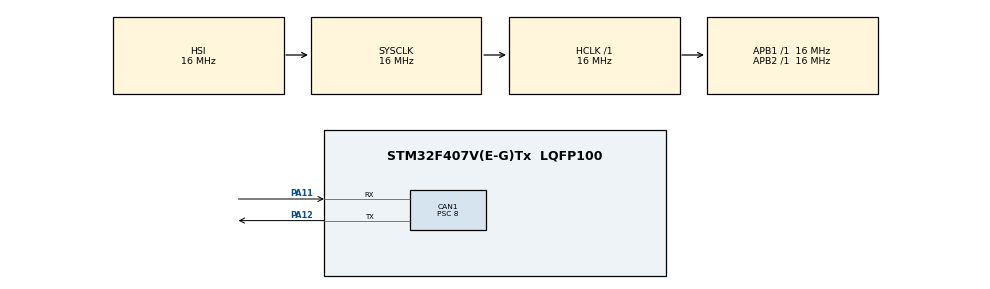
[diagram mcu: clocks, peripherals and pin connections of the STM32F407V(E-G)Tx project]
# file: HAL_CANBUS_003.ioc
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CAN1.BS1=CAN_BS1_2TQ
CAN1.CalculateBaudRate=500000
CAN1.CalculateTimeBit=2000
CAN1.CalculateTimeQuantum=500.0
CAN1.Mode=CAN_MODE_LOOPBACK
CAN1.Prescaler=8
Mcu.Family=STM32F4
Mcu.Name=STM32F407V(E-G)Tx
Mcu.Package=LQFP100
NVIC.CAN1_RX0_IRQn=true\:0\:0\:false\:false\:true\:true\:true\:true
NVIC.CAN1_RX1_IRQn=true\:0\:0\:false\:false\:true\:true\:true\:true
NVIC.PriorityGroup=NVIC_PRIORITYGROUP_4
PA11.Mode=CAN_Activate
PA11.Signal=CAN1_RX
PA12.Mode=CAN_Activate
PA12.Signal=CAN1_TX
PA13.Mode=Serial_Wire
PA13.Signal=SYS_JTMS-SWDIO
PA14.Mode=Serial_Wire
PA14.Signal=SYS_JTCK-SWCLK
PH0-OSC_IN.Mode=HSE-External-Clock-Source
PH0-OSC_IN.Signal=RCC_OSC_IN
PH1-OSC_OUT.Mode=HSE-External-Clock-Source
PH1-OSC_OUT.Signal=RCC_OSC_OUT
ProjectManager.HeapSize=0x200
ProjectManager.StackSize=0x400
ProjectManager.TargetToolchain=STM32CubeIDE
RCC.AHBFreq_Value=16000000
RCC.APB1Freq_Value=16000000
RCC.APB2Freq_Value=16000000
RCC.CortexFreq_Value=16000000
RCC.HSE_VALUE=25000000
RCC.HSI_VALUE=16000000
RCC.LSE_VALUE=32768
RCC.SYSCLKFreq_VALUE=16000000
RCC.VCOOutputFreq_Value=192000000
board=custom

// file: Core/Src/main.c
/* USER CODE BEGIN Header */
/**
  ******************************************************************************
  * @file           : main.c
  * @brief          : Main program body
  ******************************************************************************
  * @attention
  *
  * Copyright (c) 2024 STMicroelectronics.
  * All rights reserved.
  *
  * This software is licensed under terms that can be found in the LICENSE file
  * in the root directory of this software component.
  * If no LICENSE file comes with this software, it is provided AS-IS.
  *
  ******************************************************************************
  */
/* USER CODE END Header */
#include "main.h"

/* USER CODE BEGIN Includes */

CAN_TxHeaderTypeDef CanTxHeader;
CAN_RxHeaderTypeDef CanRxHeader;

uint32_t TxMailbox;
uint8_t TxData[8];
uint8_t RxData[8];
uint8_t count = 0;

/* USER CODE END Includes */

CAN_HandleTypeDef hcan1;

void SystemClock_Config(void);
static void MX_GPIO_Init(void);
static void MX_CAN1_Init(void);

/* USER CODE BEGIN 0 */

void HAL_CAN_RxFifo0MsgPendingCallback(CAN_HandleTypeDef *hcan)
{
	HAL_CAN_GetRxMessage(&hcan1, CAN_RX_FIFO0 ,&CanRxHeader , RxData);

}

/* USER CODE END 0 */

int main(void)
{

  /* MCU Configuration--------------------------------------------------------*/

  /* Reset of all peripherals, Initializes the Flash interface and the Systick. */
  HAL_Init();

  /* Configure the system clock */
  SystemClock_Config();

  /* Initialize all configured peripherals */
  MX_GPIO_Init();
  MX_CAN1_Init();
  /* USER CODE BEGIN 2 */

  HAL_CAN_Start(&hcan1);
  HAL_CAN_ActivateNotification(&hcan1, CAN_IT_RX_FIFO0_MSG_PENDING);

  CanTxHeader.DLC = 1;
  CanTxHeader.ExtId = 0;
  CanTxHeader.IDE = CAN_ID_STD;
  CanTxHeader.RTR = CAN_RTR_DATA;
  CanTxHeader.StdId = 0x103;
  CanTxHeader.TransmitGlobalTime = DISABLE;

  TxData[0] = 0xf3;

  HAL_CAN_AddTxMessage(&hcan1, &CanTxHeader, TxData, &TxMailbox);

  /* USER CODE END 2 */

  /* Infinite loop */
  while (1)
  {

  }
}

void SystemClock_Config(void)
{
  RCC_OscInitTypeDef RCC_OscInitStruct = {0};
  RCC_ClkInitTypeDef RCC_ClkInitStruct = {0};

  /** Configure the main internal regulator output voltage
  */
  __HAL_RCC_PWR_CLK_ENABLE();
  __HAL_PWR_VOLTAGESCALING_CONFIG(PWR_REGULATOR_VOLTAGE_SCALE1);

  /** Initializes the RCC Oscillators according to the specified parameters
  * in the RCC_OscInitTypeDef structure.
  */
  RCC_OscInitStruct.OscillatorType = RCC_OSCILLATORTYPE_HSI;
  RCC_OscInitStruct.HSIState = RCC_HSI_ON;
  RCC_OscInitStruct.HSICalibrationValue = RCC_HSICALIBRATION_DEFAULT;
  RCC_OscInitStruct.PLL.PLLState = RCC_PLL_NONE;
  if (HAL_RCC_OscConfig(&RCC_OscInitStruct) != HAL_OK)
  {
    Error_Handler();
  }

  /** Initializes the CPU, AHB and APB buses clocks
  */
  RCC_ClkInitStruct.ClockType = RCC_CLOCKTYPE_HCLK|RCC_CLOCKTYPE_SYSCLK
                              |RCC_CLOCKTYPE_PCLK1|RCC_CLOCKTYPE_PCLK2;
  RCC_ClkInitStruct.SYSCLKSource = RCC_SYSCLKSOURCE_HSI;
  RCC_ClkInitStruct.AHBCLKDivider = RCC_SYSCLK_DIV1;
  RCC_ClkInitStruct.APB1CLKDivider = RCC_HCLK_DIV1;
  RCC_ClkInitStruct.APB2CLKDivider = RCC_HCLK_DIV1;

  if (HAL_RCC_ClockConfig(&RCC_ClkInitStruct, FLASH_LATENCY_0) != HAL_OK)
  {
    Error_Handler();
  }
}

static void MX_CAN1_Init(void)
{

  hcan1.Instance = CAN1;
  hcan1.Init.Prescaler = 8;
  hcan1.Init.Mode = CAN_MODE_LOOPBACK;
  hcan1.Init.SyncJumpWidth = CAN_SJW_1TQ;
  hcan1.Init.TimeSeg1 = CAN_BS1_2TQ;
  hcan1.Init.TimeSeg2 = CAN_BS2_1TQ;
  hcan1.Init.TimeTriggeredMode = DISABLE;
  hcan1.Init.AutoBusOff = DISABLE;
  hcan1.Init.AutoWakeUp = DISABLE;
  hcan1.Init.AutoRetransmission = DISABLE;
  hcan1.Init.ReceiveFifoLocked = DISABLE;
  hcan1.Init.TransmitFifoPriority = DISABLE;
  if (HAL_CAN_Init(&hcan1) != HAL_OK)
  {
    Error_Handler();
  }

  // First set the Can Filter Header.
  CAN_FilterTypeDef CanFilter;

  // Enable or the disable the filter.
  CanFilter.FilterActivation = CAN_FILTER_ENABLE;

  // This parameter specifies which filter bank we want to use. It could be anything between 0 and SlaveStartFilterBank-1
  CanFilter.FilterBank = 10;

  // Select which Filter FIFO to use. In our case it is the FIFO0;
  CanFilter.FilterFIFOAssignment = CAN_FILTER_FIFO0;
  CanFilter.FilterIdHigh 	 = 0x103 << 5;
  CanFilter.FilterIdLow 	 = 0;
  CanFilter.FilterMaskIdHigh = 0x103 << 5;
  CanFilter.FilterMaskIdLow  = 0;
  CanFilter.FilterMode = CAN_FILTERMODE_IDMASK;
  CanFilter.FilterScale = CAN_FILTERSCALE_32BIT;

  // This parameter shows how much filters we want to assign to CAN1 peripheral.
  CanFilter.SlaveStartFilterBank = 13;

  HAL_CAN_ConfigFilter(&hcan1, &CanFilter);
}

static void MX_GPIO_Init(void)
{

  /* GPIO Ports Clock Enable */
  __HAL_RCC_GPIOH_CLK_ENABLE();
  __HAL_RCC_GPIOA_CLK_ENABLE();

}

void Error_Handler(void)
{
  __disable_irq();
  while (1)
  {
  }
}
